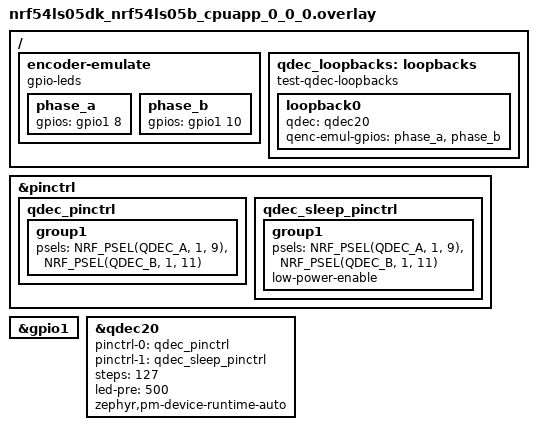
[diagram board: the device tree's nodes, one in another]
/*
 * Copyright (c) 2025 Nordic Semiconductor ASA
 *
 * SPDX-License-Identifier: LicenseRef-Nordic-5-Clause
 */

/ {
	encoder-emulate {
		compatible = "gpio-leds";

		phase_a: phase_a {
			gpios = <&gpio1 8 GPIO_ACTIVE_HIGH>;
		};

		phase_b: phase_b {
			gpios = <&gpio1 10 GPIO_ACTIVE_HIGH>;
		};
	};

	qdec_loopbacks: loopbacks {
		compatible = "test-qdec-loopbacks";

		loopback0 {
			qdec = <&qdec20>;
			qenc-emul-gpios = <&phase_a &phase_b>;
		};
	};
};

&pinctrl {
	qdec_pinctrl: qdec_pinctrl {
		group1 {
			psels = <NRF_PSEL(QDEC_A, 1, 9)>,
				<NRF_PSEL(QDEC_B, 1, 11)>;
		};
	};

	qdec_sleep_pinctrl: qdec_sleep_pinctrl {
		group1 {
			psels = <NRF_PSEL(QDEC_A, 1, 9)>,
				<NRF_PSEL(QDEC_B, 1, 11)>;
			low-power-enable;
		};
	};
};

&gpio1 {
	status = "okay";
};

&qdec20 {
	status = "okay";
	pinctrl-0 = <&qdec_pinctrl>;
	pinctrl-1 = <&qdec_sleep_pinctrl>;
	pinctrl-names = "default", "sleep";
	steps = <127>;
	led-pre = <500>;
	zephyr,pm-device-runtime-auto;
};
